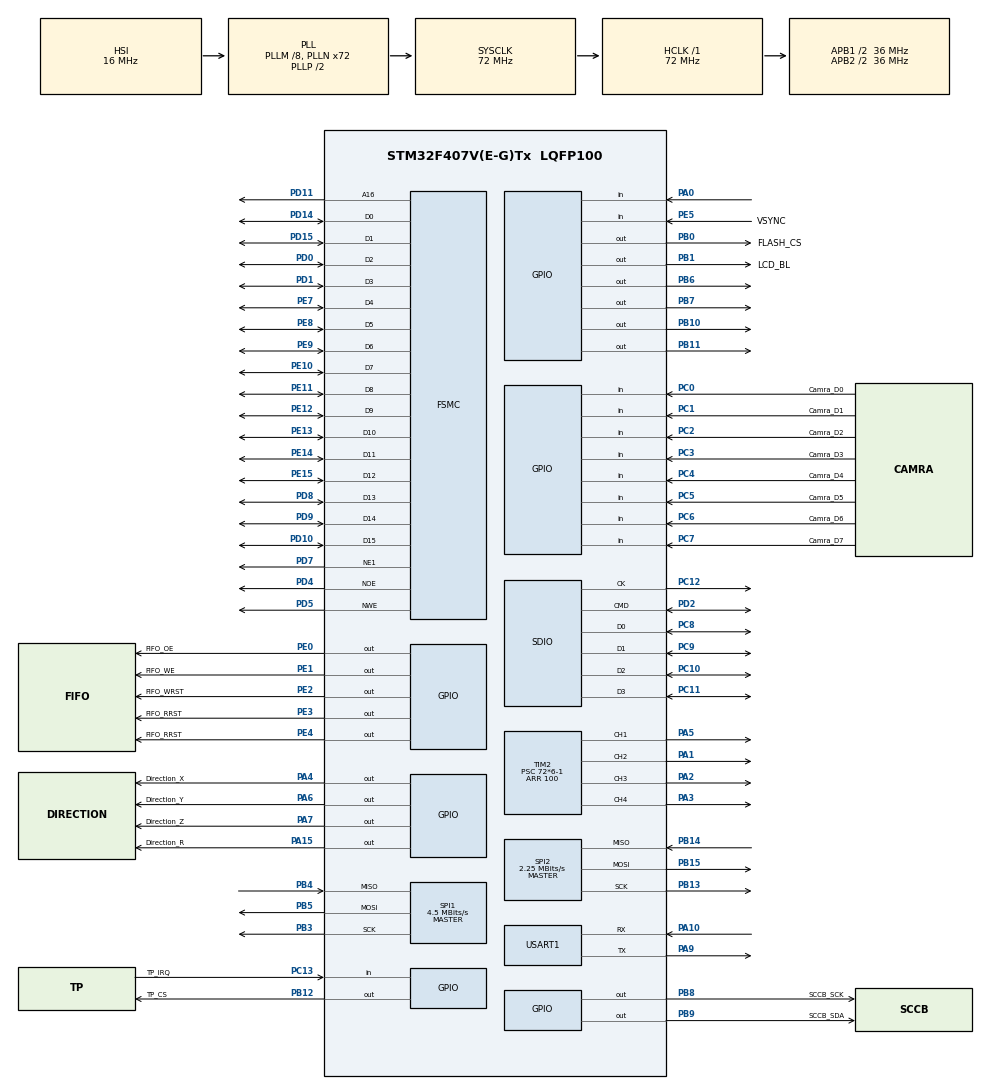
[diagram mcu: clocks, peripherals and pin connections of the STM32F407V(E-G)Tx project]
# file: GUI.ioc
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FATFS._CODE_PAGE=936
FATFS._USE_LFN=1
FSMC.AddressSetupTime1=10
FSMC.BusTurnAroundDuration1=10
FSMC.DataSetupTime1=50
Mcu.Family=STM32F4
Mcu.Name=STM32F407V(E-G)Tx
Mcu.Package=LQFP100
NVIC.PriorityGroup=NVIC_PRIORITYGROUP_4
NVIC.TIM2_IRQn=true\:2\:0\:true\:true\:true\:1\:true
PA0-WKUP.Signal=GPIO_Input
PA1.Signal=S_TIM2_CH2
PA10.Mode=Asynchronous
PA10.Signal=USART1_RX
PA13.Mode=Serial_Wire
PA13.Signal=SYS_JTMS-SWDIO
PA14.Mode=Serial_Wire
PA14.Signal=SYS_JTCK-SWCLK
PA15.GPIO_Label=Direction_R
PA15.Signal=GPIO_Output
PA2.Signal=S_TIM2_CH3
PA3.Signal=S_TIM2_CH4
PA4.GPIO_Label=Direction_X
PA4.Signal=GPIO_Output
PA5.Signal=S_TIM2_CH1_ETR
PA6.GPIO_Label=Direction_Y
PA6.Signal=GPIO_Output
PA7.GPIO_Label=Direction_Z
PA7.Signal=GPIO_Output
PA9.Mode=Asynchronous
PA9.Signal=USART1_TX
PB0.GPIO_Label=FLASH_CS
PB0.Signal=GPIO_Output
PB1.GPIO_Label=LCD_BL
PB1.Signal=GPIO_Output
PB10.Signal=GPIO_Output
PB11.Signal=GPIO_Output
PB12.GPIO_Label=TP_CS
PB12.Signal=GPIO_Output
PB13.Mode=Full_Duplex_Master
PB13.Signal=SPI2_SCK
PB14.Mode=Full_Duplex_Master
PB14.Signal=SPI2_MISO
PB15.Mode=Full_Duplex_Master
PB15.Signal=SPI2_MOSI
PB3.Mode=Full_Duplex_Master
PB3.Signal=SPI1_SCK
PB4.Mode=Full_Duplex_Master
PB4.Signal=SPI1_MISO
PB5.Mode=Full_Duplex_Master
PB5.Signal=SPI1_MOSI
PB6.PinState=GPIO_PIN_SET
PB6.Signal=GPIO_Output
PB7.PinState=GPIO_PIN_SET
PB7.Signal=GPIO_Output
PB8.GPIO_Label=SCCB_SCK
PB8.GPIO_ModeDefaultOutputPP=GPIO_MODE_OUTPUT_OD
PB8.Signal=GPIO_Output
PB9.GPIO_Label=SCCB_SDA
PB9.GPIO_ModeDefaultOutputPP=GPIO_MODE_OUTPUT_OD
PB9.Signal=GPIO_Output
PC0.GPIO_Label=Camra_D0
PC0.Signal=GPIO_Input
PC1.GPIO_Label=Camra_D1
PC1.Signal=GPIO_Input
PC10.Mode=SD_4_bits_Wide_bus
PC10.Signal=SDIO_D2
PC11.Mode=SD_4_bits_Wide_bus
PC11.Signal=SDIO_D3
PC12.Mode=SD_4_bits_Wide_bus
PC12.Signal=SDIO_CK
PC13-ANTI_TAMP.GPIO_Label=TP_IRQ
PC13-ANTI_TAMP.GPIO_PuPd=GPIO_PULLUP
PC13-ANTI_TAMP.Signal=GPIO_Input
PC14-OSC32_IN.Mode=LSE-External-Oscillator
PC14-OSC32_IN.Signal=RCC_OSC32_IN
PC15-OSC32_OUT.Mode=LSE-External-Oscillator
PC15-OSC32_OUT.Signal=RCC_OSC32_OUT
PC2.GPIO_Label=Camra_D2
PC2.Signal=GPIO_Input
PC3.GPIO_Label=Camra_D3
PC3.Signal=GPIO_Input
PC4.GPIO_Label=Camra_D4
PC4.Signal=GPIO_Input
PC5.GPIO_Label=Camra_D5
PC5.Signal=GPIO_Input
PC6.GPIO_Label=Camra_D6
PC6.Signal=GPIO_Input
PC7.GPIO_Label=Camra_D7
PC7.Signal=GPIO_Input
PC8.Mode=SD_4_bits_Wide_bus
PC8.Signal=SDIO_D0
PC9.Mode=SD_4_bits_Wide_bus
PC9.Signal=SDIO_D1
PD0.Mode=16b-d1
PD0.Signal=FSMC_D2
PD1.Mode=16b-d1
PD1.Signal=FSMC_D3
PD10.Mode=16b-d1
PD10.Signal=FSMC_D15
PD11.Mode=A16_1
PD11.Signal=FSMC_A16
PD14.Mode=16b-d1
PD14.Signal=FSMC_D0
PD15.Mode=16b-d1
PD15.Signal=FSMC_D1
PD2.Mode=SD_4_bits_Wide_bus
PD2.Signal=SDIO_CMD
PD4.Mode=Lcd1
PD4.Signal=FSMC_NOE
PD5.Mode=Lcd1
PD5.Signal=FSMC_NWE
PD7.Mode=NorPsramChipSelect1_1
PD7.Signal=FSMC_NE1
PD8.Mode=16b-d1
PD8.Signal=FSMC_D13
PD9.Mode=16b-d1
PD9.Signal=FSMC_D14
PE0.GPIO_Label=FIFO_OE
PE0.Signal=GPIO_Output
PE1.GPIO_Label=FIFO_WE
PE1.Signal=GPIO_Output
PE10.Mode=16b-d1
PE10.Signal=FSMC_D7
PE11.Mode=16b-d1
PE11.Signal=FSMC_D8
PE12.Mode=16b-d1
PE12.Signal=FSMC_D9
PE13.Mode=16b-d1
PE13.Signal=FSMC_D10
PE14.Mode=16b-d1
PE14.Signal=FSMC_D11
PE15.Mode=16b-d1
PE15.Signal=FSMC_D12
PE2.GPIO_Label=FIFO_WRST
PE2.Signal=GPIO_Output
PE3.GPIO_Label=FIFO_RRST
PE3.Signal=GPIO_Output
PE4.GPIO_Label=FIFO_RRST
PE4.Signal=GPIO_Output
PE5.GPIO_Label=VSYNC
PE5.GPIO_PuPd=GPIO_PULLDOWN
PE5.Signal=GPIO_Input
PE7.Mode=16b-d1
PE7.Signal=FSMC_D4
PE8.Mode=16b-d1
PE8.Signal=FSMC_D5
PE9.Mode=16b-d1
PE9.Signal=FSMC_D6
PH0-OSC_IN.Mode=HSE-External-Oscillator
PH0-OSC_IN.Signal=RCC_OSC_IN
PH1-OSC_OUT.Mode=HSE-External-Oscillator
PH1-OSC_OUT.Signal=RCC_OSC_OUT
ProjectManager.HeapSize=0x200
ProjectManager.StackSize=0x1000
ProjectManager.TargetToolchain=MDK-ARM V5
RCC.48MHZClocksFreq_Value=36000000
RCC.AHBFreq_Value=72000000
RCC.APB1CLKDivider=RCC_HCLK_DIV2
RCC.APB1Freq_Value=36000000
RCC.APB1TimFreq_Value=72000000
RCC.APB2CLKDivider=RCC_HCLK_DIV2
RCC.APB2Freq_Value=36000000
RCC.APB2TimFreq_Value=72000000
RCC.CortexFreq_Value=72000000
RCC.HCLKFreq_Value=72000000
RCC.HSE_VALUE=25000000
RCC.HSI_VALUE=16000000
RCC.PLLM=8
RCC.PLLN=72
RCC.RCC_RTC_Clock_Source=RCC_RTCCLKSOURCE_LSE
RCC.RCC_RTC_Clock_SourceVirtual=RCC_RTCCLKSOURCE_LSE
RCC.SYSCLKFreq_VALUE=72000000
RCC.SYSCLKSource=RCC_SYSCLKSOURCE_PLLCLK
RCC.VCOOutputFreq_Value=144000000
SDIO.ClockDiv=2
SH.S_TIM2_CH1_ETR.0=TIM2_CH1,PWM Generation1 CH1
SH.S_TIM2_CH2.0=TIM2_CH2,PWM Generation2 CH2
SH.S_TIM2_CH3.0=TIM2_CH3,PWM Generation3 CH3
SH.S_TIM2_CH4.0=TIM2_CH4,PWM Generation4 CH4
SPI1.BaudRatePrescaler=SPI_BAUDRATEPRESCALER_8
SPI1.CalculateBaudRate=4.5 MBits/s
SPI1.Direction=SPI_DIRECTION_2LINES
SPI1.Mode=SPI_MODE_MASTER
SPI1.VirtualType=VM_MASTER
SPI2.BaudRatePrescaler=SPI_BAUDRATEPRESCALER_16
SPI2.CLKPhase=SPI_PHASE_2EDGE
SPI2.CLKPolarity=SPI_POLARITY_HIGH
SPI2.CalculateBaudRate=2.25 MBits/s
SPI2.Direction=SPI_DIRECTION_2LINES
SPI2.Mode=SPI_MODE_MASTER
SPI2.VirtualType=VM_MASTER
TIM2.Channel-PWM\ Generation1\ CH1=TIM_CHANNEL_1
TIM2.Channel-PWM\ Generation2\ CH2=TIM_CHANNEL_2
TIM2.Channel-PWM\ Generation3\ CH3=TIM_CHANNEL_3
TIM2.Channel-PWM\ Generation4\ CH4=TIM_CHANNEL_4
TIM2.Period=100
TIM2.Prescaler=72*6-1
TIM2.Pulse-PWM\ Generation1\ CH1=50
TIM2.Pulse-PWM\ Generation2\ CH2=50
TIM2.Pulse-PWM\ Generation3\ CH3=50
TIM2.Pulse-PWM\ Generation4\ CH4=50
USART1.VirtualMode=VM_ASYNC
VP_CRC_VS_CRC.Mode=CRC_Activate
VP_FATFS_VS_SDIO.Mode=SDIO
VP_RTC_VS_RTC_Activate.Mode=RTC_Enabled
board=GUI

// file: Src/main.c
/**
  ******************************************************************************
  * File Name          : main.c
  * Description        : Main program body
  ******************************************************************************
  *
  * Copyright (c) 2018 STMicroelectronics International N.V.
  * All rights reserved.
  *
  * Redistribution and use in source and binary forms, with or without
  * modification, are permitted, provided that the following conditions are met:
  *
  * 1. Redistribution of source code must retain the above copyright notice,
  *    this list of conditions and the following disclaimer.
  * 2. Redistributions in binary form must reproduce the above copyright notice,
  *    this list of conditions and the following disclaimer in the documentation
  *    and/or other materials provided with the distribution.
  * 3. Neither the name of STMicroelectronics nor the names of other
  *    contributors to this software may be used to endorse or promote products
  *    derived from this software without specific written permission.
  * 4. This software, including modifications and/or derivative works of this
  *    software, must execute solely and exclusively on microcontroller or
  *    microprocessor devices manufactured by or for STMicroelectronics.
  * 5. Redistribution and use of this software other than as permitted under
  *    this license is void and will automatically terminate your rights under
  *    this license.
  *
  * THIS SOFTWARE IS PROVIDED BY STMICROELECTRONICS AND CONTRIBUTORS "AS IS"
  * AND ANY EXPRESS, IMPLIED OR STATUTORY WARRANTIES, INCLUDING, BUT NOT
  * LIMITED TO, THE IMPLIED WARRANTIES OF MERCHANTABILITY, FITNESS FOR A
  * PARTICULAR PURPOSE AND NON-INFRINGEMENT OF THIRD PARTY INTELLECTUAL PROPERTY
  * RIGHTS ARE DISCLAIMED TO THE FULLEST EXTENT PERMITTED BY LAW. IN NO EVENT
  * SHALL STMICROELECTRONICS OR CONTRIBUTORS BE LIABLE FOR ANY DIRECT, INDIRECT,
  * INCIDENTAL, SPECIAL, EXEMPLARY, OR CONSEQUENTIAL DAMAGES (INCLUDING, BUT NOT
  * LIMITED TO, PROCUREMENT OF SUBSTITUTE GOODS OR SERVICES; LOSS OF USE, DATA,
  * OR PROFITS; OR BUSINESS INTERRUPTION) HOWEVER CAUSED AND ON ANY THEORY OF
  * LIABILITY, WHETHER IN CONTRACT, STRICT LIABILITY, OR TORT (INCLUDING
  * NEGLIGENCE OR OTHERWISE) ARISING IN ANY WAY OUT OF THE USE OF THIS SOFTWARE,
  * EVEN IF ADVISED OF THE POSSIBILITY OF SUCH DAMAGE.
  *
  ******************************************************************************
  */
#include "main.h"
#include "stm32f4xx_hal.h"
#include "crc.h"
#include "fatfs.h"
#include "rtc.h"
#include "sdio.h"
#include "spi.h"
#include "tim.h"
#include "usart.h"
#include "gpio.h"
#include "fsmc.h"

/* USER CODE BEGIN Includes */
#include "GUI.h"
#include "string.h"
#include "sccb.h"
#include "ov7725.h"
#include "ILI93xx.h"
#include "touch.h"
#include "spi_flash.h"
#include "debug.h"
//#include "GUIDemo.h"

/* libunko add */
#include "string.h"
#include "rc522_function.h"
#include "rc522_config.h"
#include "manager.h"
#include "motor.h"

/* USER CODE END Includes */

/* USER CODE BEGIN PV */
/* Private variables ---------------------------------------------------------*/

/* USER CODE END PV */

void SystemClock_Config(void);
void Error_Handler(void);
static void MX_NVIC_Init(void);

extern uint8_t motor_flag;		// 电机完成标志位
extern uint8_t channel;				// 定时器通道

/* USER CODE BEGIN PFP */
/* Private function prototypes -----------------------------------------------*/

/* USER CODE END PFP */

/* USER CODE BEGIN 0 */

/*摄像头配置结构体*/
extern OV7725_MODE_PARAM cam_mode;

void Mytouch_MainTask(void);
/* USER CODE END 0 */

int main(void)
{

  /* USER CODE BEGIN 1 */
	/*文件系统*/
	FATFS fs;
	int res = -1;

	/*falsh id*/
	uint32_t FLASH_ID = 0;

	/* debug add */
	int16_t x = 0, y = 0, z = 0, r = 0;

  /* USER CODE END 1 */

  /* MCU Configuration----------------------------------------------------------*/

  /* Reset of all peripherals, Initializes the Flash interface and the Systick. */
  HAL_Init();

  /* Configure the system clock */
  SystemClock_Config();

  /* Initialize all configured peripherals */
  MX_GPIO_Init();
  MX_CRC_Init();
  MX_USART1_UART_Init();
  MX_FSMC_Init();
  MX_SDIO_SD_Init();
  MX_FATFS_Init();
  MX_RTC_Init();
  MX_SPI1_Init();
  MX_TIM2_Init();
  MX_SPI2_Init();

  /* Initialize interrupts */
  MX_NVIC_Init();

  /* USER CODE BEGIN 2 */
	printf("系统正在初始化...\r\n");
	GUI_Init();
	GUI_Clear();
	GUI_SetFont(&GUI_Font8x12_ASCII);
	GUI_DispString("The system is initializing ...");

	/* RFID Init */
	MX_SPIFlash_Init();
	PcdReset();
	M500PcdConfigISOType ( 'A' );// 设置工作方式

//	Set_Date_Time();

	/*挂载sd文件系统*/
	res = f_mount(&fs,"0:",1);
	if(res != FR_OK)
	{
		printf("请给开发板插入已格式化成fat格式的SD卡 !\r\n\n\n");
	}

	OV7725_Start();

	//这里拉高f_cs 原因是避免因为在CUBemx中没设置默认输出高 导致芯片在上电的时候就被选中 而不能正常通信
	HAL_GPIO_WritePin(GPIOB, GPIO_PIN_0 ,GPIO_PIN_SET);
	/*读取flash ID */
	FLASH_ID = SPI_FLASH_ReadID();
	printf("FLASH_ID is 0x%x\r\n", FLASH_ID);

	/*初始化触屏*/
	tp_dev.init();
	GUI_SetColor(GUI_RED);
	GUI_DrawRect(0, 0, 320-1, 240-1);
	GUI_DrawLine(0, 120, 320, 120);
	GUI_DrawLine(80, 0, 80, 240);
	GUI_DrawLine(160, 0, 160, 240);
	GUI_DrawLine(240, 0, 240, 240);
//	while(1)
//	{
//		TP_Scan(0);
//	}
  /* USER CODE END 2 */

  /* Infinite loop */
  /* USER CODE BEGIN WHILE */
  while (1)
  {
		while(1)
			manager();
//		car2_park();
//		debug();

	while(1)
	{

		while (!TP_Scan(0));
		GUI_SetColor(GUI_YELLOW);
		GUI_DispStringAt("x:",1,16);GUI_DispDec(tp_dev.x[0],3);
		GUI_DispStringAt("y:",1,32);GUI_DispDec(tp_dev.y[0],3);
		GUI_SetColor(GUI_WHITE);
		motor_flag = 1;		// 标志位置1表示未完成

		// x轴
		if (tp_dev.x[0] < 80 && tp_dev.y[0] < 120)
		{
			x++;
			channel = CHANNEL_X;
			HAL_GPIO_WritePin(Direction_X_GPIO_Port, Direction_X_Pin, X_LEFT_DIRECTION);
		}
		else if (tp_dev.x[0] < 80 && tp_dev.y[0] > 120)
		{
			x--;
			channel = CHANNEL_X;
			HAL_GPIO_WritePin(Direction_X_GPIO_Port, Direction_X_Pin, X_RIGHT_DIRECTION);
		}
		// y轴
		else if (tp_dev.x[0] > 80 && tp_dev.x[0] < 160 && tp_dev.y[0] < 120)
		{
			y++;
			channel = CHANNEL_Y;
			HAL_GPIO_WritePin(Direction_Y_GPIO_Port, Direction_Y_Pin, Y_UP_DIRECTION);
		}
		else if (tp_dev.x[0] > 80 && tp_dev.x[0] < 160 && tp_dev.y[0] > 120)
		{
			y--;
			channel = CHANNEL_Y;
			HAL_GPIO_WritePin(Direction_Y_GPIO_Port, Direction_Y_Pin, Y_DOWN_DIRECTION);
		}
		// z轴
		else if (tp_dev.x[0] > 160 && tp_dev.x[0] < 240 && tp_dev.y[0] < 120)
		{
			z++;
			channel = CHANNEL_Z;
			HAL_GPIO_WritePin(Direction_Z_GPIO_Port, Direction_Z_Pin, Z_UP_DIRECTION);
		}
		else if (tp_dev.x[0] > 160 && tp_dev.x[0] < 240 && tp_dev.y[0] > 120)
		{
			z--;
			channel = CHANNEL_Z;
			HAL_GPIO_WritePin(Direction_Z_GPIO_Port, Direction_Z_Pin, Z_DOWN_DIRECTION);
		}
		// 分度盘
		else if (tp_dev.x[0] > 240 && tp_dev.x[0] < 320 && tp_dev.y[0] < 120)
		{
			r++;
			channel = CHANNEL_R;
			HAL_GPIO_WritePin(Direction_R_GPIO_Port, Direction_R_Pin, R_UP_DIRECTION);
		}
		else if (tp_dev.x[0] > 240 && tp_dev.x[0] < 320 && tp_dev.y[0] > 120)
		{
			r--;
			channel = CHANNEL_R;
			HAL_GPIO_WritePin(Direction_R_GPIO_Port, Direction_R_Pin, R_DOWN_DIRECTION);
		}

		pulse(15);
		// 等待电机到位

		// 等待电机到位
		while (motor_flag)
		{
			HAL_Delay(10);
		}
		GUI_SetColor(GUI_GREEN);
		GUI_DispStringAt("x:", 1, 16*4);GUI_DispDec(x, 4);
		GUI_DispStringAt("y:", 1, 16*5);GUI_DispDec(y, 4);
		GUI_DispStringAt("z:", 1, 16*6);GUI_DispDec(z, 4);
		GUI_DispStringAt("r:", 1, 16*7);GUI_DispDec(r, 4);
		GUI_SetColor(GUI_WHITE);

		}

  /* USER CODE END WHILE */

  }

}

/** System Clock Configuration
*/
void SystemClock_Config(void)
{

  RCC_OscInitTypeDef RCC_OscInitStruct;
  RCC_ClkInitTypeDef RCC_ClkInitStruct;
  RCC_PeriphCLKInitTypeDef PeriphClkInitStruct;

    /**Configure the main internal regulator output voltage
    */
  __HAL_RCC_PWR_CLK_ENABLE();

  __HAL_PWR_VOLTAGESCALING_CONFIG(PWR_REGULATOR_VOLTAGE_SCALE1);

    /**Initializes the CPU, AHB and APB busses clocks
    */
  RCC_OscInitStruct.OscillatorType = RCC_OSCILLATORTYPE_HSI|RCC_OSCILLATORTYPE_LSE;
  RCC_OscInitStruct.LSEState = RCC_LSE_ON;
  RCC_OscInitStruct.HSIState = RCC_HSI_ON;
  RCC_OscInitStruct.HSICalibrationValue = 16;
  RCC_OscInitStruct.PLL.PLLState = RCC_PLL_ON;
  RCC_OscInitStruct.PLL.PLLSource = RCC_PLLSOURCE_HSI;
  RCC_OscInitStruct.PLL.PLLM = 8;
  RCC_OscInitStruct.PLL.PLLN = 72;
  RCC_OscInitStruct.PLL.PLLP = RCC_PLLP_DIV2;
  RCC_OscInitStruct.PLL.PLLQ = 4;
  if (HAL_RCC_OscConfig(&RCC_OscInitStruct) != HAL_OK)
  {
    Error_Handler();
  }

    /**Initializes the CPU, AHB and APB busses clocks
    */
  RCC_ClkInitStruct.ClockType = RCC_CLOCKTYPE_HCLK|RCC_CLOCKTYPE_SYSCLK
                              |RCC_CLOCKTYPE_PCLK1|RCC_CLOCKTYPE_PCLK2;
  RCC_ClkInitStruct.SYSCLKSource = RCC_SYSCLKSOURCE_PLLCLK;
  RCC_ClkInitStruct.AHBCLKDivider = RCC_SYSCLK_DIV1;
  RCC_ClkInitStruct.APB1CLKDivider = RCC_HCLK_DIV2;
  RCC_ClkInitStruct.APB2CLKDivider = RCC_HCLK_DIV2;

  if (HAL_RCC_ClockConfig(&RCC_ClkInitStruct, FLASH_LATENCY_2) != HAL_OK)
  {
    Error_Handler();
  }

  PeriphClkInitStruct.PeriphClockSelection = RCC_PERIPHCLK_RTC;
  PeriphClkInitStruct.RTCClockSelection = RCC_RTCCLKSOURCE_LSE;
  if (HAL_RCCEx_PeriphCLKConfig(&PeriphClkInitStruct) != HAL_OK)
  {
    Error_Handler();
  }

    /**Configure the Systick interrupt time
    */
  HAL_SYSTICK_Config(HAL_RCC_GetHCLKFreq()/1000);

    /**Configure the Systick
    */
  HAL_SYSTICK_CLKSourceConfig(SYSTICK_CLKSOURCE_HCLK);

  /* SysTick_IRQn interrupt configuration */
  HAL_NVIC_SetPriority(SysTick_IRQn, 0, 0);
}

/** NVIC Configuration
*/
static void MX_NVIC_Init(void)
{
  /* TIM2_IRQn interrupt configuration */
  HAL_NVIC_SetPriority(TIM2_IRQn, 2, 0);
  HAL_NVIC_EnableIRQ(TIM2_IRQn);
}

/* USER CODE BEGIN 4 */
void Mytouch_MainTask(void)
{
GUI_PID_STATE TouchState;
int xPhys;
int yPhys;
GUI_Init();
GUI_SetFont(&GUI_Font20_ASCII);
GUI_CURSOR_Show();
GUI_CURSOR_Select(&GUI_CursorCrossL);
GUI_SetBkColor(GUI_WHITE);
GUI_SetColor(GUI_BLACK);
GUI_Clear();
GUI_DispString("Measurement of\nA/D converter values");
while (1)
{
GUI_TOUCH_GetState(&TouchState); // Get the touch position in pixel
//xPhys = GUI_TOUCH_GetxPhys(); // Get the A/D mesurement result in x
//yPhys = GUI_TOUCH_GetyPhys(); // Get the A/D mesurement result in y
xPhys = GUI_TOUCH_X_MeasureX(); // Get the A/D mesurement result in x
yPhys = GUI_TOUCH_X_MeasureY(); // Get the A/D mesurement result in y
GUI_SetColor(GUI_BLUE);
GUI_DispStringAt("Analog input:\n", 0, 40);
GUI_GotoY(GUI_GetDispPosY() + 2);
	GUI_DispString("x:");
GUI_DispDec(xPhys, 4);
GUI_DispString(", y:");
GUI_DispDec(yPhys, 4);
GUI_SetColor(GUI_RED);
GUI_GotoY(GUI_GetDispPosY() + 4);
GUI_DispString("\nPosition:\n");
GUI_GotoY(GUI_GetDispPosY() + 2);
GUI_DispString("x:");
GUI_DispDec(TouchState.x,4);
GUI_DispString(", y:");
GUI_DispDec(TouchState.y,4);
HAL_Delay(50);
};
}
/* USER CODE END 4 */

void Error_Handler(void)
{
  while(1)
  {
  }
}

/************************ (C) COPYRIGHT STMicroelectronics *****END OF FILE****/
